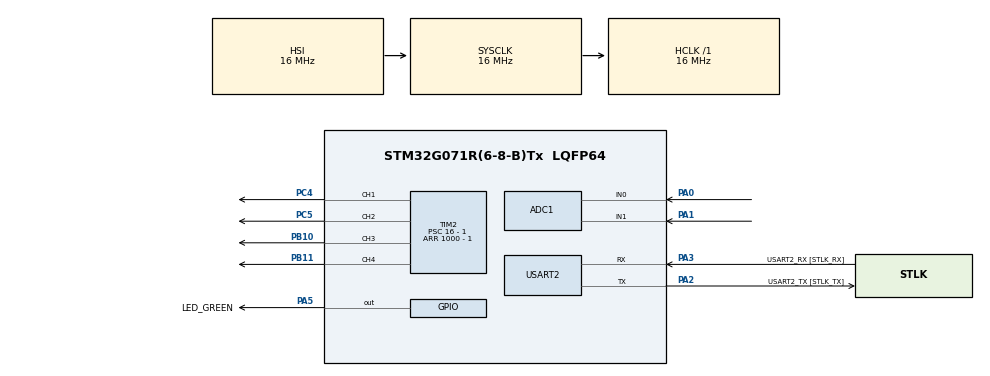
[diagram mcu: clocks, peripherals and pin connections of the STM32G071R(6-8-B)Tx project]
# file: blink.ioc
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ADC1.Channel-2\#ChannelRegularConversion=ADC_CHANNEL_0
ADC1.NbrOfConversionFlag=1
ADC1.Rank-2\#ChannelRegularConversion=1
ADC1.SamplingTime-2\#ChannelRegularConversion=ADC_SAMPLINGTIME_COMMON_1
ADC1.SelectedChannel=ADC_CHANNEL_0|ADC_CHANNEL_1
ADC1.master=1
Mcu.Family=STM32G0
Mcu.Name=STM32G071R(6-8-B)Tx
Mcu.Package=LQFP64
NVIC.TIM2_IRQn=true\:0\:0\:false\:false\:true\:true\:true\:true
PA0.Mode=IN0
PA0.Signal=ADC1_IN0
PA1.Mode=IN1
PA1.Signal=ADC1_IN1
PA13.GPIO_Label=TMS
PA13.Mode=Serial_Wire
PA13.Signal=SYS_SWDIO
PA14-BOOT0.GPIO_Label=TCK
PA14-BOOT0.Mode=Serial_Wire
PA14-BOOT0.Signal=SYS_SWCLK
PA2.GPIO_Label=USART2_TX [STLK_TX]
PA2.GPIO_PuPd=GPIO_PULLUP
PA2.Mode=Asynchronous
PA2.Signal=USART2_TX
PA3.GPIO_Label=USART2_RX [STLK_RX]
PA3.GPIO_PuPd=GPIO_PULLUP
PA3.Mode=Asynchronous
PA3.Signal=USART2_RX
PA5.GPIO_Label=LED_GREEN
PA5.GPIO_Speed=GPIO_SPEED_FREQ_HIGH
PA5.Signal=GPIO_Output
PB10.Signal=S_TIM2_CH3
PB11.Signal=S_TIM2_CH4
PC13.Mode=SYS_WakeUp1
PC13.Signal=SYS_WKUP2
PC14-OSC32_IN\ (PC14).Mode=LSE-External-Oscillator
PC14-OSC32_IN\ (PC14).Signal=RCC_OSC32_IN
PC15-OSC32_OUT\ (PC15).Mode=LSE-External-Oscillator
PC15-OSC32_OUT\ (PC15).Signal=RCC_OSC32_OUT
PC4.Signal=S_TIM2_CH1_ETR
PC5.Signal=S_TIM2_CH2
PF0-OSC_IN\ (PF0).GPIO_Label=MCO
PF0-OSC_IN\ (PF0).Mode=HSE-External-Clock-Source
PF0-OSC_IN\ (PF0).Signal=RCC_OSC_IN
ProjectManager.HeapSize=0x200
ProjectManager.StackSize=0x400
ProjectManager.TargetToolchain=MDK-ARM V5.32
RCC.AHBFreq_Value=16000000
RCC.CortexFreq_Value=16000000
RCC.EXTERNAL_CLOCK_VALUE=12288000
RCC.HCLKFreq_Value=16000000
RCC.HSE_VALUE=8000000
RCC.HSI_VALUE=16000000
RCC.SYSCLKFreq_VALUE=16000000
RCC.VCOOutputFreq_Value=128000000
SH.S_TIM2_CH1_ETR.0=TIM2_CH1,PWM Generation1 CH1
SH.S_TIM2_CH2.0=TIM2_CH2,PWM Generation2 CH2
SH.S_TIM2_CH3.0=TIM2_CH3,PWM Generation3 CH3
SH.S_TIM2_CH4.0=TIM2_CH4,PWM Generation4 CH4
TIM2.Channel-PWM\ Generation1\ CH1=TIM_CHANNEL_1
TIM2.Channel-PWM\ Generation2\ CH2=TIM_CHANNEL_2
TIM2.Channel-PWM\ Generation3\ CH3=TIM_CHANNEL_3
TIM2.Channel-PWM\ Generation4\ CH4=TIM_CHANNEL_4
TIM2.Period=1000 - 1
TIM2.Prescaler=16 - 1
USART2.VirtualMode-Asynchronous=VM_ASYNC
VP_SYS_VS_DBSignals.Mode=DisableDeadBatterySignals
VP_TIM2_VS_ClockSourceINT.Mode=Internal
board=NUCLEO-G071RB

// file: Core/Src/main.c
/* USER CODE BEGIN Header */
/**
  ******************************************************************************
  * @file           : main.c
  * @brief          : Main program body
  ******************************************************************************
  * @attention
  *
  * Copyright (c) 2024 STMicroelectronics.
  * All rights reserved.
  *
  * This software is licensed under terms that can be found in the LICENSE file
  * in the root directory of this software component.
  * If no LICENSE file comes with this software, it is provided AS-IS.
  *
  ******************************************************************************
  */
/* USER CODE END Header */
#include "main.h"
#include "adc.h"
#include "tim.h"
#include "usart.h"
#include "gpio.h"

/* USER CODE BEGIN Includes */
#include "run.h"
/* USER CODE END Includes */

void SystemClock_Config(void);

int main(void)
{

  /* MCU Configuration--------------------------------------------------------*/

  /* Reset of all peripherals, Initializes the Flash interface and the Systick. */
  HAL_Init();

  /* Configure the system clock */
  SystemClock_Config();

  /* Initialize all configured peripherals */
  MX_GPIO_Init();
  MX_USART2_UART_Init();
  MX_ADC1_Init();
  MX_TIM2_Init();
  /* USER CODE BEGIN 2 */
	HAL_ADCEx_Calibration_Start(&hadc1);
	HAL_TIM_Base_Start_IT(&htim2);
	HAL_TIM_PWM_Start(&htim2, TIM_CHANNEL_1);
	HAL_TIM_PWM_Start(&htim2, TIM_CHANNEL_2);
	HAL_TIM_PWM_Start(&htim2, TIM_CHANNEL_3);
	HAL_TIM_PWM_Start(&htim2, TIM_CHANNEL_4);

  /* USER CODE END 2 */

  /* Infinite loop */
  while (1)
  {

    /* USER CODE BEGIN 3 */
	  loop();
  }
  /* USER CODE END 3 */
}

void SystemClock_Config(void)
{
  RCC_OscInitTypeDef RCC_OscInitStruct = {0};
  RCC_ClkInitTypeDef RCC_ClkInitStruct = {0};

  /** Configure the main internal regulator output voltage
  */
  HAL_PWREx_ControlVoltageScaling(PWR_REGULATOR_VOLTAGE_SCALE1);

  /** Initializes the RCC Oscillators according to the specified parameters
  * in the RCC_OscInitTypeDef structure.
  */
  RCC_OscInitStruct.OscillatorType = RCC_OSCILLATORTYPE_HSI;
  RCC_OscInitStruct.HSIState = RCC_HSI_ON;
  RCC_OscInitStruct.HSIDiv = RCC_HSI_DIV1;
  RCC_OscInitStruct.HSICalibrationValue = RCC_HSICALIBRATION_DEFAULT;
  RCC_OscInitStruct.PLL.PLLState = RCC_PLL_NONE;
  if (HAL_RCC_OscConfig(&RCC_OscInitStruct) != HAL_OK)
  {
    Error_Handler();
  }

  /** Initializes the CPU, AHB and APB buses clocks
  */
  RCC_ClkInitStruct.ClockType = RCC_CLOCKTYPE_HCLK|RCC_CLOCKTYPE_SYSCLK
                              |RCC_CLOCKTYPE_PCLK1;
  RCC_ClkInitStruct.SYSCLKSource = RCC_SYSCLKSOURCE_HSI;
  RCC_ClkInitStruct.AHBCLKDivider = RCC_SYSCLK_DIV1;
  RCC_ClkInitStruct.APB1CLKDivider = RCC_HCLK_DIV1;

  if (HAL_RCC_ClockConfig(&RCC_ClkInitStruct, FLASH_LATENCY_0) != HAL_OK)
  {
    Error_Handler();
  }
}

/* USER CODE BEGIN 4 */
uint32_t cnt = 0;
void HAL_TIM_PeriodElapsedCallback(TIM_HandleTypeDef *htim){
	cnt++;
	timer_loop();
}
/* USER CODE END 4 */

void Error_Handler(void)
{
  __disable_irq();
  while (1)
  {
  }
}
